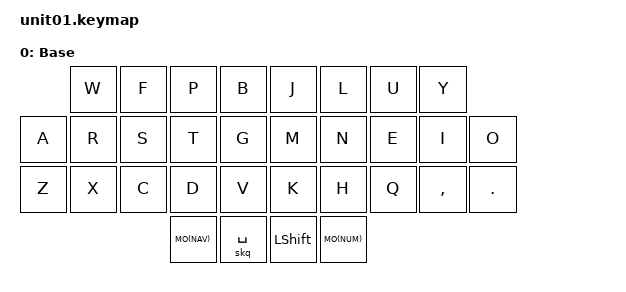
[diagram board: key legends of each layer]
/*
 * Copyright (c) 2021 Nick Winans
 *
 * SPDX-License-Identifier: MIT
 */

#include <behaviors.dtsi>
#include <dt-bindings/zmk/keys.h>
#include <dt-bindings/zmk/bt.h>


&sk {
  release-after-ms = <STICKY_KEY_TIMEOUT>;
};

&caps_word {
  continue-list = <UNDERSCORE MINUS BACKSPACE>;
};

&kscan0 {
  debounce-period = <14>;
};

/ {
	keymap {
		compatible = "zmk,keymap";
		
		base_layer {
			label = "Base";
			bindings = <
        // 							 ╭─────────────┬─────────────┬─────────────┬─────────────╮   ╭─────────────┬─────────────┬─────────────┬─────────────╮
            			         &kp W         &kp F         &kp P         &kp B             &kp J         &kp L         &kp U         &kp Y        
        // ╭─────────────┼─────────────┼─────────────┼─────────────┼─────────────┤   ├─────────────┼─────────────┼─────────────┼─────────────┼─────────────╮
             &kp A         &kp R         &kp S         &kp T         &kp G             &kp M         &kp N         &kp E         &kp I         &kp O
        // ├─────────────┼─────────────┼─────────────┼─────────────┼─────────────┤   ├─────────────┼─────────────┼─────────────┼─────────────┼─────────────┤
             &kp Z         &kp X         &kp C         &kp D         &kp V             &kp K         &kp H         &kp Q     		 &kp COMMA     &kp DOT
        // ╰─────────────┴─────────────┴─────────────┼─────────────┼─────────────┤   ├─────────────┼─────────────┼─────────────┴─────────────┴─────────────╯
                                                       MO(NAV)       &skq SPACE       &kp LSHIFT     MO(NUM)
        //                                           ╰─────────────┴─────────────╯   ╰─────────────┴─────────────╯
      >;
		};
	};
};
